VERSION ""

NS_ :

BS_:
BU_: INV U2C HV_BMS ECU_FRONT ECU_REAR DSH TCU LV_BMS SGL
BO_ 560 BrakePressure: 4 ECU_FRONT
   SG_ BrakeSensor1 : 0|16@1- (0.1,0) [0|0] "psi" Vector__XXX
   SG_ BrakeSensor2 : 16|16@1- (0.1,0) [0|0] "psi" Vector__XXX

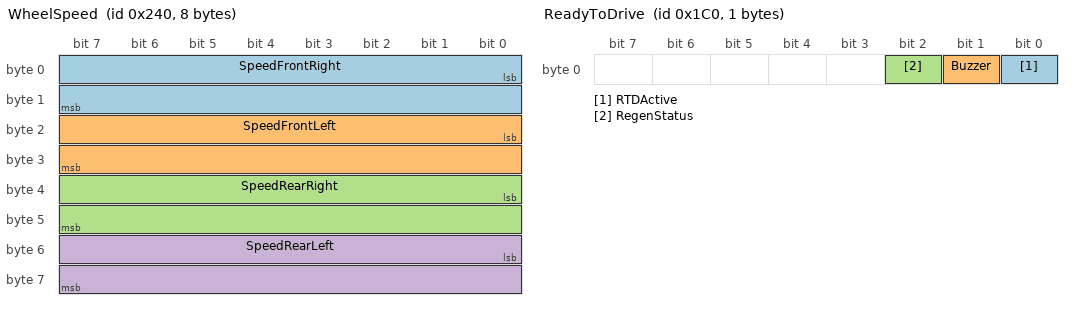
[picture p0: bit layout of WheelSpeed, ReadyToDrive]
BO_ 576 WheelSpeed: 8 ECU_FRONT
   SG_ SpeedFrontRight : 0|16@1- (1,0) [0|0] "rpm" Vector__XXX
   SG_ SpeedFrontLeft : 16|16@1- (1,0) [0|0] "rpm" Vector__XXX
   SG_ SpeedRearRight : 32|16@1- (1,0) [0|0] "rpm" Vector__XXX
   SG_ SpeedRearLeft : 48|16@1- (1,0) [0|0] "rpm" Vector__XXX

BO_ 608 MBRTempSens: 2 ECU_REAR
   SG_ Temperature : 0|12@1- (0.0625,0) [-40|128] "degC" Vector__XXX

BO_ 448 ReadyToDrive: 1 ECU_FRONT
   SG_ RTDActive : 0|1@1+ (1,0) [0|1] "" Vector__XXX
   SG_ Buzzer : 1|1@1+ (1,0) [0|1] "" Vector__XXX
   SG_ RegenStatus : 2|1@1+ (1,0) [0|1] "" Vector__XXX

BO_ 1280 CANHeartBeatLED: 1 ECU_REAR
   SG_ HeartBit : 0|1@1+ (1,0) [0|1] "" Vector__XXX

BO_ 688 APPS: 4 ECU_FRONT
   SG_ APPS1 : 0|16@1- (0.01,0) [0|0] "percent" Vector__XXX
   SG_ APPS2 : 16|16@1- (0.01,0) [0|0] "percent" Vector__XXX

BO_ 528 BrakeLight: 1 ECU_FRONT
   SG_ BrakeLightActive : 0|1@1+ (1,0) [0|1] "" Vector__XXX

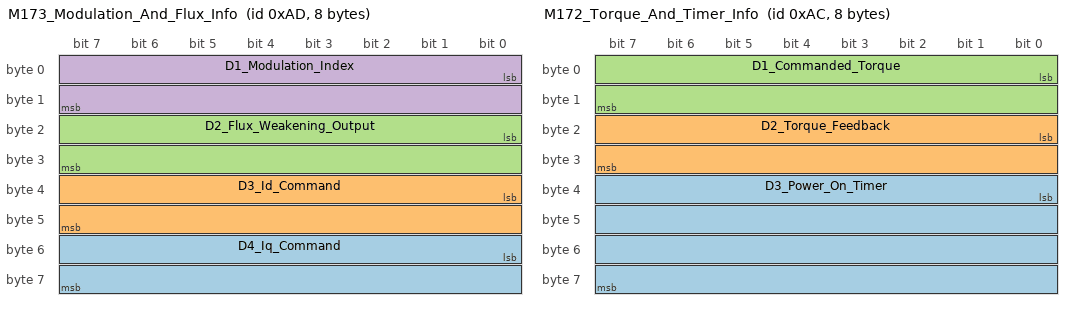
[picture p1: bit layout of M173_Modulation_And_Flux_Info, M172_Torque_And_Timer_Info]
BO_ 173 M173_Modulation_And_Flux_Info: 8 INV
   SG_ D4_Iq_Command : 48|16@1- (0.1,0) [-3276.8|3276.7] "A" Vector__XXX
   SG_ D3_Id_Command : 32|16@1- (0.1,0) [-3276.8|3276.7] "A" Vector__XXX
   SG_ D2_Flux_Weakening_Output : 16|16@1- (0.1,0) [-3276.8|3276.7] "A" Vector__XXX
   SG_ D1_Modulation_Index : 0|16@1- (0.0001,0) [-3.2768|3.2767] "" Vector__XXX

BO_ 172 M172_Torque_And_Timer_Info: 8 INV
   SG_ D3_Power_On_Timer : 32|32@1+ (0.003,0) [0|1.28848e+07] "sec" Vector__XXX
   SG_ D2_Torque_Feedback : 16|16@1- (0.1,0) [-3276.8|3276.7] "Nm" Vector__XXX
   SG_ D1_Commanded_Torque : 0|16@1- (0.1,0) [-3276.8|3276.7] "Nm" Vector__XXX

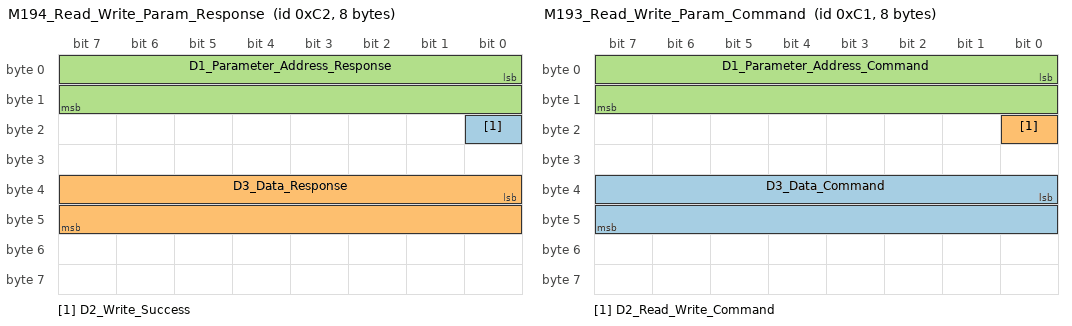
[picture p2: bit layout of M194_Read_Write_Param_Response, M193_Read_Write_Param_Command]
BO_ 194 M194_Read_Write_Param_Response: 8 INV
   SG_ D2_Write_Success : 16|1@1+ (1,0) [0|1] "" Vector__XXX
   SG_ D3_Data_Response : 32|16@1- (1,0) [-32768|32767] "" Vector__XXX
   SG_ D1_Parameter_Address_Response : 0|16@1+ (1,0) [0|65535] "" Vector__XXX

BO_ 193 M193_Read_Write_Param_Command: 8 ECU_FRONT
   SG_ D3_Data_Command : 32|16@1- (1,0) [-32768|32767] "" Vector__XXX
   SG_ D2_Read_Write_Command : 16|1@1+ (1,0) [0|1] "" Vector__XXX
   SG_ D1_Parameter_Address_Command : 0|16@1+ (1,0) [0|65535] "" Vector__XXX

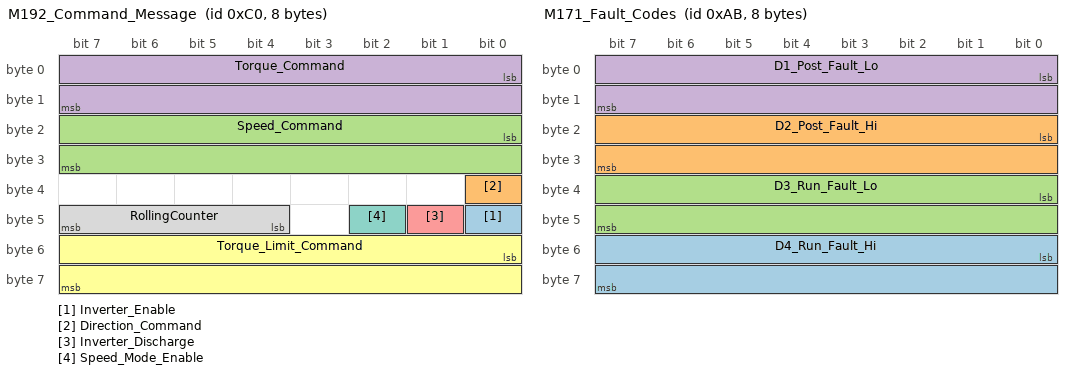
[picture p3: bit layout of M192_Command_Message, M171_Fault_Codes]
BO_ 192 M192_Command_Message: 8 ECU_FRONT
   SG_ Inverter_Enable : 40|1@1+ (1,0) [0|1] "Bit" Vector__XXX
   SG_ Direction_Command : 32|1@1+ (1,0) [0|1] "Bit" Vector__XXX
   SG_ Speed_Command : 16|16@1- (1,0) [-32768|32767] "rpm" Vector__XXX
   SG_ Torque_Command : 0|16@1- (0.1,0) [-3276.8|3276.7] "Nm" Vector__XXX
   SG_ Inverter_Discharge : 41|1@1+ (1,0) [0|1] "Bit" Vector__XXX
   SG_ Torque_Limit_Command : 48|16@1- (0.1,0) [-3276.8|3276.7] "Nm" Vector__XXX
   SG_ Speed_Mode_Enable : 42|1@1+ (1,0) [0|1] "Bit" Vector__XXX
   SG_ RollingCounter : 44|4@1+ (1,0) [0|15] "Bits" Vector__XXX

BO_ 171 M171_Fault_Codes: 8 INV
   SG_ D4_Run_Fault_Hi : 48|16@1+ (1,0) [0|65535] "" Vector__XXX
   SG_ D2_Post_Fault_Hi : 16|16@1+ (1,0) [0|65535] "" Vector__XXX
   SG_ D3_Run_Fault_Lo : 32|16@1+ (1,0) [0|65535] "" Vector__XXX
   SG_ D1_Post_Fault_Lo : 0|16@1+ (1,0) [0|65535] "" Vector__XXX

BO_ 170 M170_Internal_States: 8 INV
   SG_ D7_Direction_Command : 56|1@1+ (1,0) [0|1] "" Vector__XXX
   SG_ D6_Inverter_Enable_State : 48|1@1+ (1,0) [0|1] "" Vector__XXX
   SG_ D3_Relay_3_Status : 26|1@1+ (1,0) [0|1] "" Vector__XXX
   SG_ D3_Relay_4_Status : 27|1@1+ (1,0) [0|1] "" Vector__XXX
   SG_ D3_Relay_2_Status : 25|1@1+ (1,0) [0|1] "" Vector__XXX
   SG_ D4_Inverter_Run_Mode : 32|1@1+ (1,0) [0|1] "" Vector__XXX
   SG_ D5_Inverter_Command_Mode : 40|1@1+ (1,0) [0|1] "" Vector__XXX
   SG_ D3_Relay_1_Status : 24|1@1+ (1,0) [0|1] "" Vector__XXX
   SG_ D2_Inverter_State : 16|8@1+ (1,0) [0|255] "" Vector__XXX
   SG_ D1_VSM_State : 0|8@1+ (1,0) [0|15] "" Vector__XXX
   SG_ D6_Inverter_Enable_Lockout : 55|1@1+ (1,0) [0|1] "" Vector__XXX
   SG_ D4_Inverter_Discharge_State : 37|3@1+ (1,0) [0|7] "" Vector__XXX
   SG_ D3_Relay_5_Status : 28|1@1+ (1,0) [0|1] "" Vector__XXX
   SG_ D3_Relay_6_Status : 29|1@1+ (1,0) [0|1] "" Vector__XXX
   SG_ D7_BMS_Active : 57|1@1+ (1,0) [0|1] "" Vector__XXX
   SG_ D7_BMS_Torque_Limiting : 58|1@1+ (1,0) [0|1] "" Vector__XXX
   SG_ D7_Max_Speed_Limiting : 59|1@1+ (1,0) [0|1] "" Vector__XXX
   SG_ D7_Low_Speed_Limiting : 61|1@1+ (1,0) [0|1] "" Vector__XXX
   SG_ D5_Rolling_Counter : 44|4@1+ (1,0) [0|15] "" Vector__XXX
   SG_ D1_PWM_Frequency : 8|8@1+ (1,0) [0|255] "kHz" Vector__XXX
   SG_ D6_Start_Mode_Active : 54|1@1+ (1,0) [0|1] "" Vector__XXX

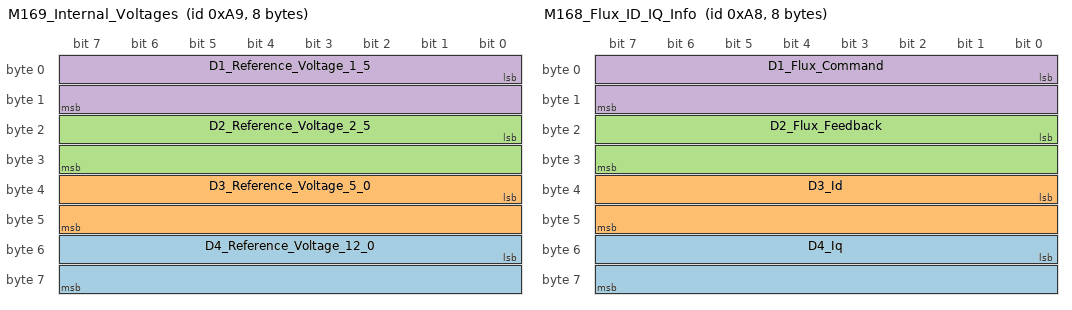
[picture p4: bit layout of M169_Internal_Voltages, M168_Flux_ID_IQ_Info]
BO_ 169 M169_Internal_Voltages: 8 INV
   SG_ D4_Reference_Voltage_12_0 : 48|16@1- (0.01,0) [-327.68|327.67] "V" Vector__XXX
   SG_ D3_Reference_Voltage_5_0 : 32|16@1- (0.01,0) [-327.68|327.67] "V" Vector__XXX
   SG_ D2_Reference_Voltage_2_5 : 16|16@1- (0.01,0) [-327.68|327.67] "V" Vector__XXX
   SG_ D1_Reference_Voltage_1_5 : 0|16@1- (0.01,0) [-327.68|327.67] "V" Vector__XXX

BO_ 168 M168_Flux_ID_IQ_Info: 8 INV
   SG_ D4_Iq : 48|16@1- (0.1,0) [-3276.8|3276.7] "A" Vector__XXX
   SG_ D3_Id : 32|16@1- (0.1,0) [-3276.8|3276.7] "A" Vector__XXX
   SG_ D2_Flux_Feedback : 16|16@1- (0.001,0) [-32.768|32.767] "Wb" Vector__XXX
   SG_ D1_Flux_Command : 0|16@1- (0.001,0) [-32.768|32.767] "Wb" Vector__XXX

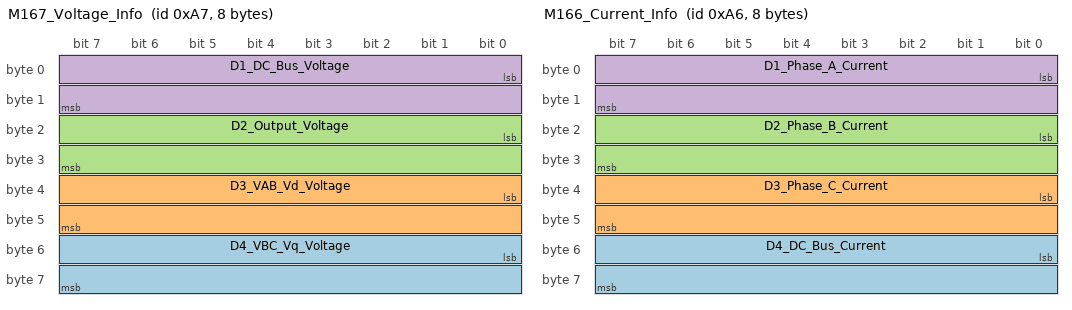
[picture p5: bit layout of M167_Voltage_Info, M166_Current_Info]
BO_ 167 M167_Voltage_Info: 8 INV
   SG_ D4_VBC_Vq_Voltage : 48|16@1- (0.1,0) [-3276.8|3276.7] "V" Vector__XXX
   SG_ D3_VAB_Vd_Voltage : 32|16@1- (0.1,0) [-3276.8|3276.7] "V" Vector__XXX
   SG_ D2_Output_Voltage : 16|16@1- (0.1,0) [-3276.8|3276.7] "V" Vector__XXX
   SG_ D1_DC_Bus_Voltage : 0|16@1- (0.1,0) [-3276.8|3276.7] "V" Vector__XXX

BO_ 166 M166_Current_Info: 8 INV
   SG_ D4_DC_Bus_Current : 48|16@1- (0.1,0) [-3276.8|3276.7] "A" Vector__XXX
   SG_ D3_Phase_C_Current : 32|16@1- (0.1,0) [-3276.8|3276.7] "A" Vector__XXX
   SG_ D2_Phase_B_Current : 16|16@1- (0.1,0) [-3276.8|3276.7] "A" Vector__XXX
   SG_ D1_Phase_A_Current : 0|16@1- (0.1,0) [-3276.8|3276.7] "A" Vector__XXX

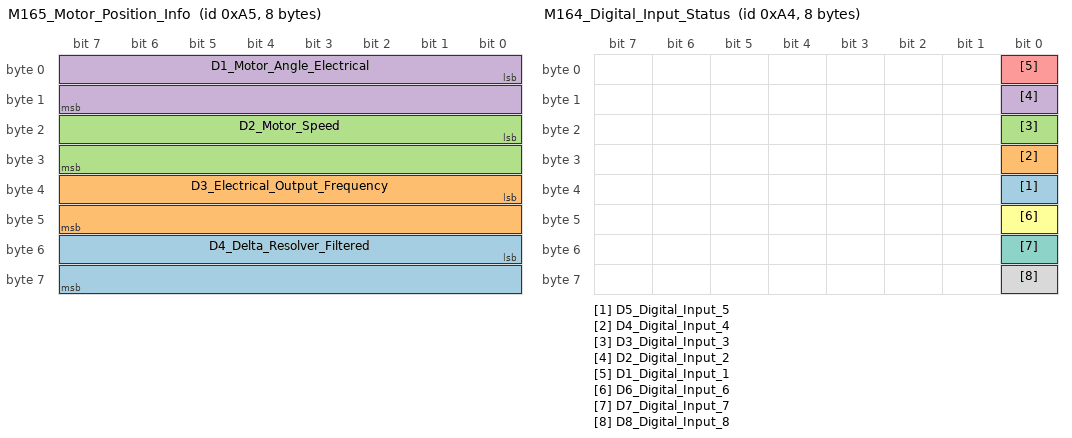
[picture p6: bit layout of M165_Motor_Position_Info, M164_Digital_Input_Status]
BO_ 165 M165_Motor_Position_Info: 8 INV
   SG_ D4_Delta_Resolver_Filtered : 48|16@1- (0.1,0) [-3276.8|3276.7] "deg" Vector__XXX
   SG_ D3_Electrical_Output_Frequency : 32|16@1- (0.1,0) [-3276.8|3276.7] "Hz" Vector__XXX
   SG_ D2_Motor_Speed : 16|16@1- (1,0) [-32768|32767] "rpm" Vector__XXX
   SG_ D1_Motor_Angle_Electrical : 0|16@1+ (0.1,0) [0|6553.5] "deg" Vector__XXX

BO_ 164 M164_Digital_Input_Status: 8 INV
   SG_ D5_Digital_Input_5 : 32|1@1+ (1,0) [0|1] "boolean" Vector__XXX
   SG_ D4_Digital_Input_4 : 24|1@1+ (1,0) [0|1] "boolean" Vector__XXX
   SG_ D3_Digital_Input_3 : 16|1@1+ (1,0) [0|1] "boolean" Vector__XXX
   SG_ D2_Digital_Input_2 : 8|1@1+ (1,0) [0|1] "boolean" Vector__XXX
   SG_ D1_Digital_Input_1 : 0|1@1+ (1,0) [0|1] "boolean" Vector__XXX
   SG_ D6_Digital_Input_6 : 40|1@1+ (1,0) [0|1] "boolean" Vector__XXX
   SG_ D7_Digital_Input_7 : 48|1@1+ (1,0) [0|1] "boolean" Vector__XXX
   SG_ D8_Digital_Input_8 : 56|1@1+ (1,0) [0|1] "boolean" Vector__XXX

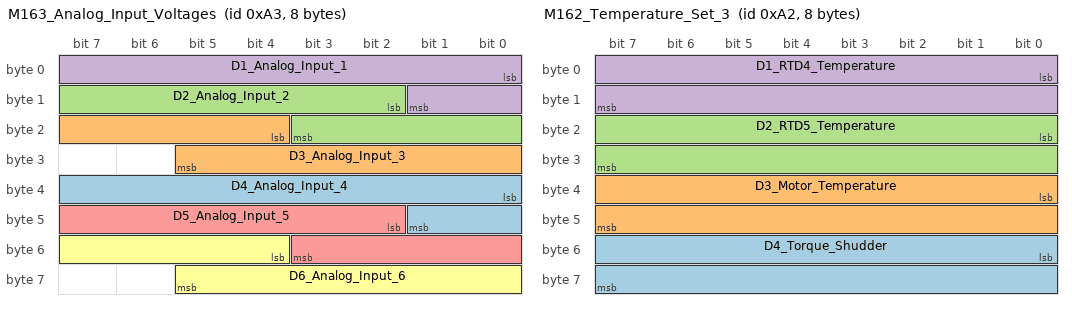
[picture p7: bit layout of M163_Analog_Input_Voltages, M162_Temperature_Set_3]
BO_ 163 M163_Analog_Input_Voltages: 8 INV
   SG_ D4_Analog_Input_4 : 32|10@1+ (0.01,0) [0|10.23] "V" Vector__XXX
   SG_ D3_Analog_Input_3 : 20|10@1+ (0.01,0) [0|10.23] "V" Vector__XXX
   SG_ D2_Analog_Input_2 : 10|10@1+ (0.01,0) [0|10.23] "V" Vector__XXX
   SG_ D1_Analog_Input_1 : 0|10@1+ (0.01,0) [0|10.23] "V" Vector__XXX
   SG_ D5_Analog_Input_5 : 42|10@1+ (0.01,0) [0|10.23] "V" Vector__XXX
   SG_ D6_Analog_Input_6 : 52|10@1+ (0.01,0) [0|10.23] "V" Vector__XXX

BO_ 162 M162_Temperature_Set_3: 8 INV
   SG_ D4_Torque_Shudder : 48|16@1- (0.1,0) [-3276.8|3276.7] "Nm" Vector__XXX
   SG_ D3_Motor_Temperature : 32|16@1- (0.1,0) [-3276.8|3276.7] "degC" Vector__XXX
   SG_ D2_RTD5_Temperature : 16|16@1- (0.1,0) [-3276.8|3276.7] "degC" Vector__XXX
   SG_ D1_RTD4_Temperature : 0|16@1- (0.1,0) [-3276.8|3276.7] "degC" Vector__XXX

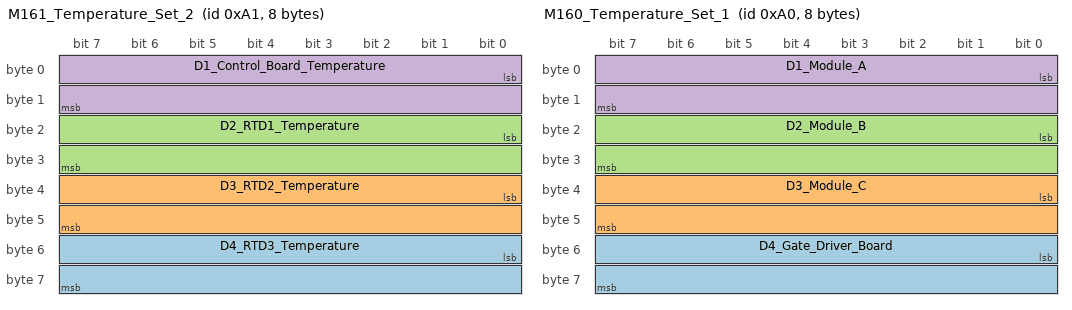
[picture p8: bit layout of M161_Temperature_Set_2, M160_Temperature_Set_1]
BO_ 161 M161_Temperature_Set_2: 8 INV
   SG_ D4_RTD3_Temperature : 48|16@1- (0.1,0) [-3276.8|3276.7] "degC" Vector__XXX
   SG_ D3_RTD2_Temperature : 32|16@1- (0.1,0) [-3276.8|3276.7] "degC" Vector__XXX
   SG_ D2_RTD1_Temperature : 16|16@1- (0.1,0) [-3276.8|3276.7] "degC" Vector__XXX
   SG_ D1_Control_Board_Temperature : 0|16@1- (0.1,0) [-3276.8|3276.7] "degC" Vector__XXX

BO_ 160 M160_Temperature_Set_1: 8 INV
   SG_ D4_Gate_Driver_Board : 48|16@1- (0.1,0) [-3276.8|3276.7] "degC" Vector__XXX
   SG_ D3_Module_C : 32|16@1- (0.1,0) [-3276.8|3276.7] "degC" Vector__XXX
   SG_ D2_Module_B : 16|16@1- (0.1,0) [-3276.8|3276.7] "degC" Vector__XXX
   SG_ D1_Module_A : 0|16@1- (0.1,0) [-3276.8|3276.7] "degC" Vector__XXX

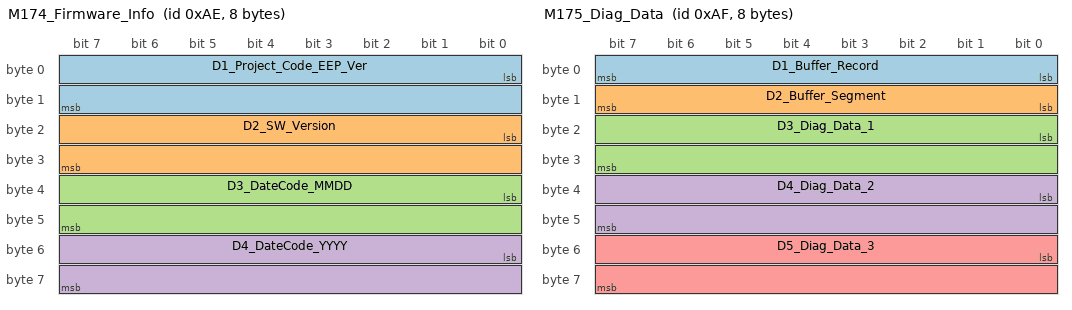
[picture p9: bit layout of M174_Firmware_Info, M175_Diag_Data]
BO_ 174 M174_Firmware_Info: 8 INV
   SG_ D1_Project_Code_EEP_Ver : 0|16@1+ (1,0) [0|65535] "" Vector__XXX
   SG_ D2_SW_Version : 16|16@1+ (1,0) [0|65535] "" Vector__XXX
   SG_ D3_DateCode_MMDD : 32|16@1+ (1,0) [0|65535] "" Vector__XXX
   SG_ D4_DateCode_YYYY : 48|16@1+ (1,0) [0|65535] "" Vector__XXX

BO_ 175 M175_Diag_Data: 8 INV
   SG_ D1_Buffer_Record : 0|8@1+ (1,0) [0|255] "" Vector__XXX
   SG_ D2_Buffer_Segment : 8|8@1+ (1,0) [0|5] "" Vector__XXX
   SG_ D3_Diag_Data_1 : 16|16@1- (1,0) [-32768|32767] "" Vector__XXX
   SG_ D4_Diag_Data_2 : 32|16@1- (1,0) [-32768|32767] "" Vector__XXX
   SG_ D5_Diag_Data_3 : 48|16@1- (1,0) [-32768|32767] "" Vector__XXX

BO_ 471 M187_U2C_Command_Txd: 8 INV
   SG_ D1_ID_Byte : 0|8@1+ (1,0) [0|255] "" Vector__XXX
   SG_ D2_Setpoint_Calc : 8|8@1+ (1,0) [0|255] "" Vector__XXX

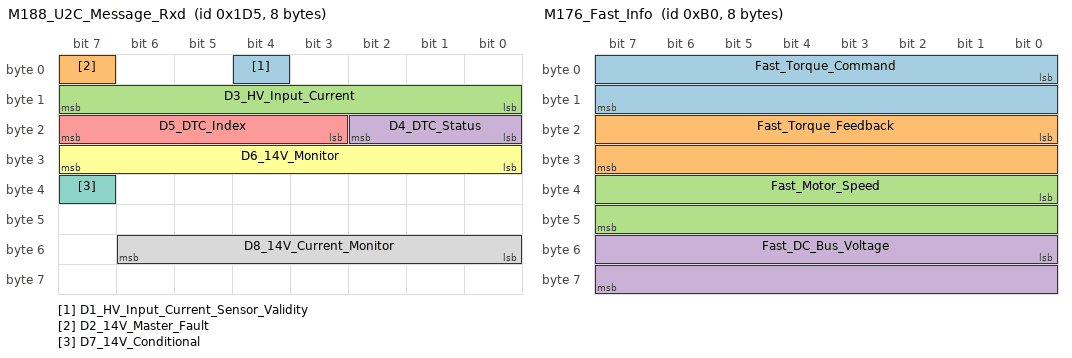
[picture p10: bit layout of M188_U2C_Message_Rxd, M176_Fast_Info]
BO_ 469 M188_U2C_Message_Rxd: 8 U2C
   SG_ D1_HV_Input_Current_Sensor_Validity : 4|1@1+ (1,0) [0|1] "" Vector__XXX
   SG_ D2_14V_Master_Fault : 7|1@1+ (1,0) [0|1] "" Vector__XXX
   SG_ D3_HV_Input_Current : 8|8@1+ (1,0) [0|255] "" Vector__XXX
   SG_ D4_DTC_Status : 16|3@1+ (1,0) [0|7] "" Vector__XXX
   SG_ D5_DTC_Index : 19|5@1+ (1,0) [0|31] "" Vector__XXX
   SG_ D6_14V_Monitor : 24|8@1+ (1,0) [0|255] "" Vector__XXX
   SG_ D7_14V_Conditional : 39|1@1+ (1,0) [0|1] "" Vector__XXX
   SG_ D8_14V_Current_Monitor : 48|7@1+ (1,0) [0|127] "" Vector__XXX

BO_ 176 M176_Fast_Info: 8 INV
   SG_ Fast_Torque_Command : 0|16@1- (0.1,0) [-3276.8|3276.7] "Nm" Vector__XXX
   SG_ Fast_Torque_Feedback : 16|16@1- (0.1,0) [-3276.8|3276.7] "Nm" Vector__XXX
   SG_ Fast_Motor_Speed : 32|16@1- (1,0) [-32768|32767] "rpm" Vector__XXX
   SG_ Fast_DC_Bus_Voltage : 48|16@1- (0.1,0) [-3276.8|3276.7] "V" Vector__XXX

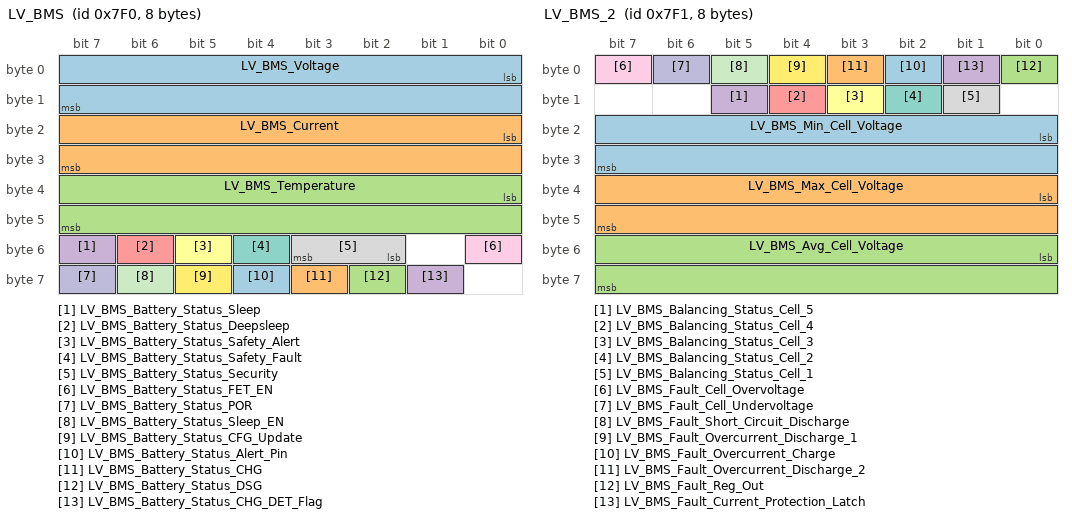
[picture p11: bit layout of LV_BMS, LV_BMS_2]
BO_ 2032 LV_BMS: 8 LV_BMS
   SG_ LV_BMS_Voltage : 0|16@1+ (1,0) [0|0] "mV" Vector__XXX
   SG_ LV_BMS_Current : 16|16@1- (1,0) [0|0] "mA" Vector__XXX
   SG_ LV_BMS_Temperature : 32|16@1+ (1,0) [0|0] "degC" Vector__XXX
   SG_ LV_BMS_Battery_Status_Sleep : 55|1@1+ (1,0) [0|1] "" Vector__XXX
   SG_ LV_BMS_Battery_Status_Deepsleep : 54|1@1+ (1,0) [0|1] "" Vector__XXX
   SG_ LV_BMS_Battery_Status_Safety_Alert : 53|1@1+ (1,0) [0|1] "" Vector__XXX
   SG_ LV_BMS_Battery_Status_Safety_Fault : 52|1@1+ (1,0) [0|1] "" Vector__XXX
   SG_ LV_BMS_Battery_Status_Security : 50|2@1+ (1,0) [0|1] "" Vector__XXX
   SG_ LV_BMS_Battery_Status_FET_EN : 48|1@1+ (1,0) [0|1] "" Vector__XXX
   SG_ LV_BMS_Battery_Status_POR : 63|1@1+ (1,0) [0|1] "" Vector__XXX
   SG_ LV_BMS_Battery_Status_Sleep_EN : 62|1@1+ (1,0) [0|1] "" Vector__XXX
   SG_ LV_BMS_Battery_Status_CFG_Update : 61|1@1+ (1,0) [0|1] "" Vector__XXX
   SG_ LV_BMS_Battery_Status_Alert_Pin : 60|1@1+ (1,0) [0|1] "" Vector__XXX
   SG_ LV_BMS_Battery_Status_CHG : 59|1@1+ (1,0) [0|1] "" Vector__XXX
   SG_ LV_BMS_Battery_Status_DSG : 58|1@1+ (1,0) [0|1] "" Vector__XXX
   SG_ LV_BMS_Battery_Status_CHG_DET_Flag : 57|1@1+ (1,0) [0|1] "" Vector__XXX

BO_ 2033 LV_BMS_2: 8 LV_BMS
   SG_ LV_BMS_Min_Cell_Voltage : 16|16@1+ (1,0) [0|0] "mV" Vector__XXX
   SG_ LV_BMS_Max_Cell_Voltage : 32|16@1+ (1,0) [0|0] "mV" Vector__XXX
   SG_ LV_BMS_Avg_Cell_Voltage : 48|16@1+ (1,0) [0|0] "mV" Vector__XXX
   SG_ LV_BMS_Balancing_Status_Cell_5 : 13|1@1+ (1,0) [0|0] "" Vector__XXX
   SG_ LV_BMS_Balancing_Status_Cell_4 : 12|1@1+ (1,0) [0|0] "" Vector__XXX
   SG_ LV_BMS_Balancing_Status_Cell_3 : 11|1@1+ (1,0) [0|0] "" Vector__XXX
   SG_ LV_BMS_Balancing_Status_Cell_2 : 10|1@1+ (1,0) [0|0] "" Vector__XXX
   SG_ LV_BMS_Balancing_Status_Cell_1 : 9|1@1+ (1,0) [0|0] "" Vector__XXX
   SG_ LV_BMS_Fault_Cell_Overvoltage : 7|1@1+ (1,0) [0|1] "" Vector__XXX
   SG_ LV_BMS_Fault_Cell_Undervoltage : 6|1@1+ (1,0) [0|1] "" Vector__XXX
   SG_ LV_BMS_Fault_Short_Circuit_Discharge : 5|1@1+ (1,0) [0|1] "" Vector__XXX
   SG_ LV_BMS_Fault_Overcurrent_Discharge_1 : 4|1@1+ (1,0) [0|1] "" Vector__XXX
   SG_ LV_BMS_Fault_Overcurrent_Charge : 2|1@1+ (1,0) [0|1] "" Vector__XXX
   SG_ LV_BMS_Fault_Overcurrent_Discharge_2 : 3|1@1+ (1,0) [0|1] "" Vector__XXX
   SG_ LV_BMS_Fault_Reg_Out : 0|1@1+ (1,0) [0|1] "" Vector__XXX
   SG_ LV_BMS_Fault_Current_Protection_Latch : 1|1@1+ (1,0) [0|1] "" Vector__XXX

BO_ 195 BMS_Fault: 4 HV_BMS
   SG_ SEG1OV : 0|1@1+ (1,0) [0|1] "" Vector__XXX
   SG_ SEG1UV : 1|1@1+ (1,0) [0|1] "" Vector__XXX
   SG_ SEG1OT : 2|1@1+ (1,0) [0|1] "" Vector__XXX
   SG_ SEG1UT : 3|1@1+ (1,0) [0|1] "" Vector__XXX
   SG_ SEG2OV : 4|1@1+ (1,0) [0|1] "" Vector__XXX
   SG_ SEG2UV : 5|1@1+ (1,0) [0|1] "" Vector__XXX
   SG_ SEG2OT : 6|1@1+ (1,0) [0|1] "" Vector__XXX
   SG_ SEG2UT : 7|1@1+ (1,0) [0|1] "" Vector__XXX
   SG_ SEG3OV : 8|1@1+ (1,0) [0|1] "" Vector__XXX
   SG_ SEG3UV : 9|1@1+ (1,0) [0|1] "" Vector__XXX
   SG_ SEG3OT : 10|1@1+ (1,0) [0|1] "" Vector__XXX
   SG_ SEG3UT : 11|1@1+ (1,0) [0|1] "" Vector__XXX
   SG_ SEG4OV : 12|1@1+ (1,0) [0|1] "" Vector__XXX
   SG_ SEG4UV : 13|1@1+ (1,0) [0|1] "" Vector__XXX
   SG_ SEG4OT : 14|1@1+ (1,0) [0|1] "" Vector__XXX
   SG_ SEG4UT : 15|1@1+ (1,0) [0|1] "" Vector__XXX
   SG_ SEG5OV : 16|1@1+ (1,0) [0|1] "" Vector__XXX
   SG_ SEG5UV : 17|1@1+ (1,0) [0|1] "" Vector__XXX
   SG_ SEG5OT : 18|1@1+ (1,0) [0|1] "" Vector__XXX
   SG_ SEG5UT : 19|1@1+ (1,0) [0|1] "" Vector__XXX
   SG_ SEG6OV : 20|1@1+ (1,0) [0|1] "" Vector__XXX
   SG_ SEG6UV : 21|1@1+ (1,0) [0|1] "" Vector__XXX
   SG_ SEG6OT : 22|1@1+ (1,0) [0|1] "" Vector__XXX
   SG_ SEG6UT : 23|1@1+ (1,0) [0|1] "" Vector__XXX
   SG_ PACKOC : 24|1@1+ (1,0) [0|1] "" Vector__XXX
   SG_ IMD_Fault : 25|1@1+ (1,0) [0|1] "" Vector__XXX
   SG_ PEC_ERROR : 26|1@1+ (1,0) [0|1] "" Vector__XXX

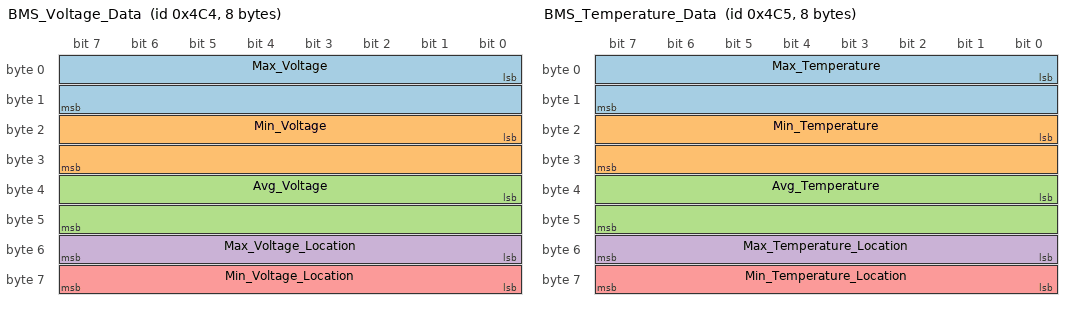
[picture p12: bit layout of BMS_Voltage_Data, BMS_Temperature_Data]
BO_ 1220 BMS_Voltage_Data: 8 HV_BMS
   SG_ Max_Voltage : 0|16@1- (0.00015,1.5) [0|0] "V" Vector__XXX
   SG_ Min_Voltage : 16|16@1- (0.00015,1.5) [0|0] "V" Vector__XXX
   SG_ Avg_Voltage : 32|16@1- (0.00015,1.5) [0|0] "V" Vector__XXX
   SG_ Max_Voltage_Location : 48|8@1+ (1,0) [0|0] "" Vector__XXX
   SG_ Min_Voltage_Location : 56|8@1+ (1,0) [0|0] "" Vector__XXX

BO_ 1221 BMS_Temperature_Data: 8 HV_BMS
   SG_ Max_Temperature : 0|16@1- (0.01,0) [0|0] "degC" Vector__XXX
   SG_ Min_Temperature : 16|16@1- (0.01,0) [0|0] "degC" Vector__XXX
   SG_ Avg_Temperature : 32|16@1- (0.01,0) [0|0] "degC" Vector__XXX
   SG_ Max_Temperature_Location : 48|8@1+ (1,0) [0|0] "" Vector__XXX
   SG_ Min_Temperature_Location : 56|8@1+ (1,0) [0|0] "" Vector__XXX

BO_ 1222 BMS_Pack_Data: 4 HV_BMS
   SG_ Pack_Voltage : 0|16@1+ (0.01,0) [0|0] "V" Vector__XXX
   SG_ Pack_Current : 16|16@1- (0.01,0) [0|0] "A" Vector__XXX

BO_ 1300 CAN_Bus_Data: 2 TCU
   SG_ Bus_Load : 0|16@1+ (0.01,0) [0|0] "percent" Vector__XXX

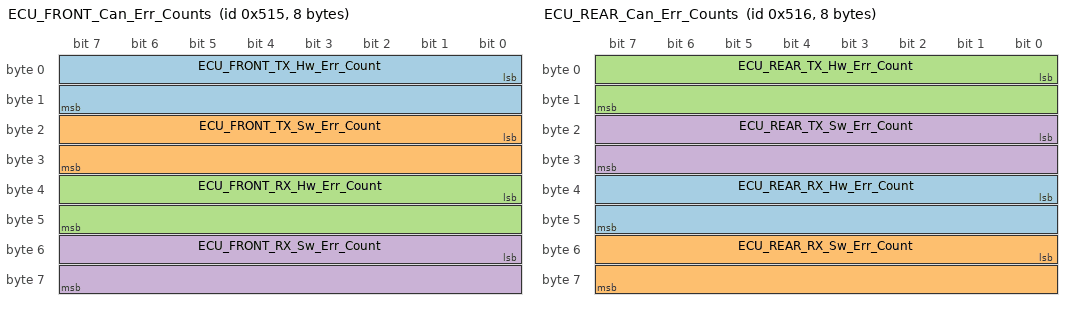
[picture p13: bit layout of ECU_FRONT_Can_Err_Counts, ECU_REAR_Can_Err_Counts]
BO_ 1301 ECU_FRONT_Can_Err_Counts: 8 ECU_FRONT
   SG_ ECU_FRONT_TX_Hw_Err_Count : 0|16@1+ (1,0) [0|0] "Errors" Vector__XXX
   SG_ ECU_FRONT_TX_Sw_Err_Count : 16|16@1+ (1,0) [0|0] "Errors" Vector__XXX
   SG_ ECU_FRONT_RX_Hw_Err_Count : 32|16@1+ (1,0) [0|0] "Errors" Vector__XXX
   SG_ ECU_FRONT_RX_Sw_Err_Count : 48|16@1+ (1,0) [0|0] "Errors" Vector__XXX

BO_ 656 ECU_REAR_Brake_Temp: 3 ECU_REAR
   SG_ ECU_REAR_Brake_Temp_RR : 0|10@1+ (1,0) [0|800] "degC" Vector__XXX
   SG_ ECU_REAR_Brake_Temp_RL : 10|10@1+ (1,0) [0|800] "degC" Vector__XXX

BO_ 640 ECU_FRONT_BrakeTemp: 3 ECU_FRONT
   SG_ ECU_FRONT_BrakeTemp_FR : 0|10@1+ (1,0) [0|800] "degC" Vector__XXX
   SG_ ECU_FRONT_BrakeTemp_FL : 10|10@1+ (1,0) [0|800] "degC" Vector__XXX

BO_ 1302 ECU_REAR_Can_Err_Counts: 8 ECU_REAR
   SG_ ECU_REAR_RX_Hw_Err_Count : 32|16@1+ (1,0) [0|0] "Errors" Vector__XXX
   SG_ ECU_REAR_RX_Sw_Err_Count : 48|16@1+ (1,0) [0|0] "Errors" Vector__XXX
   SG_ ECU_REAR_TX_Hw_Err_Count : 0|16@1+ (1,0) [0|0] "Errors" Vector__XXX
   SG_ ECU_REAR_TX_Sw_Err_Count : 16|16@1+ (1,0) [0|0] "Errors" Vector__XXX

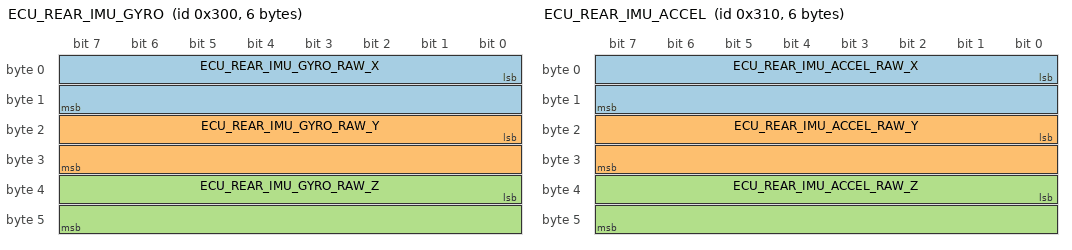
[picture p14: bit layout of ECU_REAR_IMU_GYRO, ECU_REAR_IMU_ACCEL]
BO_ 768 ECU_REAR_IMU_GYRO: 6 ECU_REAR
   SG_ ECU_REAR_IMU_GYRO_RAW_X : 0|16@1- (0.1,0) [-3276.8|3276.7] "deg/s" Vector__XXX
   SG_ ECU_REAR_IMU_GYRO_RAW_Y : 16|16@1- (0.1,0) [-3276.8|3276.7] "deg/s" Vector__XXX
   SG_ ECU_REAR_IMU_GYRO_RAW_Z : 32|16@1- (0.1,0) [-3276.6|3276.7] "deg/s" Vector__XXX

BO_ 784 ECU_REAR_IMU_ACCEL: 6 ECU_REAR
   SG_ ECU_REAR_IMU_ACCEL_RAW_X : 0|16@1- (0.001,0) [-32.768|32.767] "g" Vector__XXX
   SG_ ECU_REAR_IMU_ACCEL_RAW_Y : 16|16@1- (0.001,0) [-32.768|32.767] "g" Vector__XXX
   SG_ ECU_REAR_IMU_ACCEL_RAW_Z : 32|16@1- (0.001,0) [-32.768|32.767] "g" Vector__XXX

BO_ 592 SteeringPot: 2 ECU_FRONT
   SG_ SteeringPotAngle : 0|12@1- (0.1,0) [0|0] "" Vector__XXX

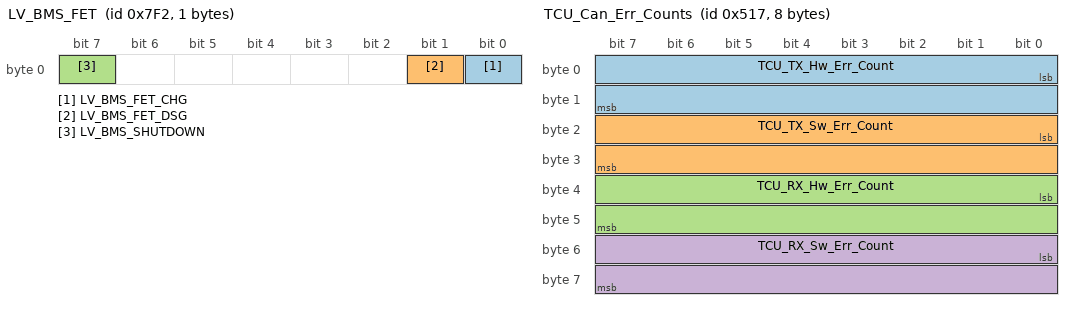
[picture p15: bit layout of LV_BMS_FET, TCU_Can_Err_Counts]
BO_ 2034 LV_BMS_FET: 1 LV_BMS
   SG_ LV_BMS_FET_CHG : 0|1@1+ (1,0) [0|1] "" Vector__XXX
   SG_ LV_BMS_FET_DSG : 1|1@1+ (1,0) [0|1] "" Vector__XXX
   SG_ LV_BMS_SHUTDOWN : 7|1@1+ (1,0) [0|1] "" Vector__XXX

BO_ 1303 TCU_Can_Err_Counts: 8 TCU
   SG_ TCU_TX_Hw_Err_Count : 0|16@1+ (1,0) [0|0] "Errors" Vector__XXX
   SG_ TCU_TX_Sw_Err_Count : 16|16@1+ (1,0) [0|0] "Errors" Vector__XXX
   SG_ TCU_RX_Hw_Err_Count : 32|16@1+ (1,0) [0|0] "Errors" Vector__XXX
   SG_ TCU_RX_Sw_Err_Count : 48|16@1+ (1,0) [0|0] "Errors" Vector__XXX

BO_ 800 SGL_Strain_Gauges_1_2: 8 SGL
   SG_ SGL_Strain_Gauge_1 : 0|32@1+ (1,0) [0|0] "" Vector__XXX
   SG_ SGL_Strain_Gauge_2 : 32|32@1+ (1,0) [0|0] "" Vector__XXX

BO_ 801 SGL_Strain_Gauges_3_4: 8 SGL
   SG_ SGL_Strain_Gauge_3 : 0|32@1+ (1,0) [0|0] "" Vector__XXX
   SG_ SGL_Strain_Gauge_4 : 32|32@1+ (1,0) [0|0] "" Vector__XXX

BO_ 802 SGL_Strain_Gauges_5_6: 8 SGL
   SG_ SGL_Strain_Gauge_5 : 0|32@1+ (1,0) [0|0] "" Vector__XXX
   SG_ SGL_Strain_Gauge_6 : 32|32@1+ (1,0) [0|0] "" Vector__XXX

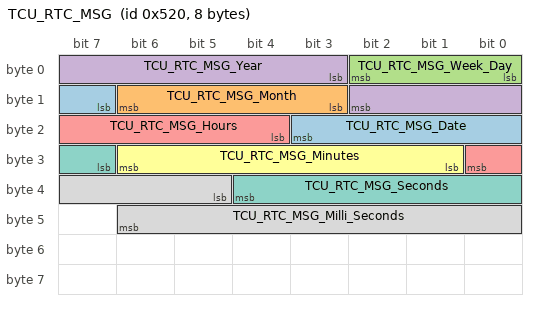
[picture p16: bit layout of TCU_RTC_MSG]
BO_ 1312 TCU_RTC_MSG: 8 TCU
   SG_ TCU_RTC_MSG_Date : 15|5@1+ (1,0) [0|31] "" Vector__XXX
   SG_ TCU_RTC_MSG_Month : 11|4@1+ (1,0) [1|12] "" Vector__XXX
   SG_ TCU_RTC_MSG_Week_Day : 0|3@1+ (1,0) [1|7] "" Vector__XXX
   SG_ TCU_RTC_MSG_Year : 3|8@1+ (1,0) [0|99] "" Vector__XXX
   SG_ TCU_RTC_MSG_Hours : 20|5@1+ (1,0) [0|23] "" Vector__XXX
   SG_ TCU_RTC_MSG_Minutes : 25|6@1+ (1,0) [0|59] "" Vector__XXX
   SG_ TCU_RTC_MSG_Seconds : 31|6@1+ (1,0) [0|59] "" Vector__XXX
   SG_ TCU_RTC_MSG_Milli_Seconds : 37|10@1+ (1,0) [0|999] "" Vector__XXX

BO_ 1313 TCU_RTC_REQ: 1 TCU
   SG_ TCU_RTC_REQ_Sig : 0|1@1+ (1,0) [0|1] "" Vector__XXX

CM_ BU_ INV "The Cascadia Motion inverter";
CM_ BU_ U2C "Delphi DC/DC Converter";
CM_ BU_ HV_BMS "High Voltage Battery Management System";
CM_ BU_ ECU_FRONT "Electronic Control Unit on Megaboard Front";
CM_ BU_ ECU_REAR "Electronic Control Unit on Megaboard Rear";
CM_ BU_ DSH "Aim Dashboard";
CM_ BU_ TCU "Telematics Control Unit on Megaboard Rear";
CM_ BU_ LV_BMS "Low Voltage Battery Management System";
CM_ BU_ SGL "Strain Gauge Logger";
CM_ SG_ 173 D4_Iq_Command "The commanded Q-axis current";
CM_ SG_ 173 D3_Id_Command "The commanded D-axis current";
CM_ SG_ 173 D2_Flux_Weakening_Output "This is the current output of the flux regulator.";
CM_ SG_ 173 D1_Modulation_Index "This is the modulation index. The scale factor is x100. To get the actual modulation index divide the value by 100.";
CM_ SG_ 172 D3_Power_On_Timer "Updated every 3 msec. This will roll over in approximately 150 days!";
CM_ SG_ 172 D2_Torque_Feedback "Estimated motor torque feedback";
CM_ SG_ 172 D1_Commanded_Torque "The commanded Torque";
CM_ BO_ 194 "The inverter response to each Parameter message that is received.";
CM_ SG_ 194 D2_Write_Success "0=Write failure, 1=Success";
CM_ SG_ 194 D3_Data_Response "All EEPROM data is 16 bits and is contained in bytes 4 and 5. Bytes 6 and 7 should be ignored.";
CM_ SG_ 194 D1_Parameter_Address_Response "Valid EEPROM Parameter CAN addresses are between 100 and 499.";
CM_ BO_ 193 "Parameter Message sent as needed by VCU to request info, change EEPROM, or command a function.";
CM_ SG_ 193 D3_Data_Command "All EEPROM data is 16 bits and is contained in bytes 4 and 5.";
CM_ SG_ 193 D2_Read_Write_Command "0=Read, 1=Write";
CM_ SG_ 193 D1_Parameter_Address_Command "Valid EEPROM Parameter CAN addresses are between 100 and 499.";
CM_ BO_ 192 "The command message is used to transmit data to the controller. This message is sent from a user supplied external controller to the PMxxx controller.";
CM_ SG_ 192 Inverter_Enable "0=Inverter OFF, 1 = Inverter ON";
CM_ SG_ 192 Direction_Command "0=CW, 1=CCW as veiwed from the shaft end of the motor";
CM_ SG_ 192 Speed_Command "Speed commandused when in speed mode";
CM_ SG_ 192 Torque_Command "Torque command when in torque mode";
CM_ SG_ 192 Inverter_Discharge "0=Discharge_Disable, 1=Discharge_Enable";
CM_ SG_ 192 Torque_Limit_Command "Torque Limit, set to 0 to keep default";
CM_ SG_ 192 Speed_Mode_Enable "0 = No change to mode, 1 = change to speed mode from torque mode";
CM_ SG_ 192 RollingCounter "Rolling Counter command";
CM_ SG_ 171 D4_Run_Fault_Hi "Each bit represents a fault. Please refer to PM100 Users Manual for details.";
CM_ SG_ 171 D2_Post_Fault_Hi "Each bit represents a fault. Please refer to PM100 Users Manual for details.";
CM_ SG_ 171 D3_Run_Fault_Lo "Each bit represents a fault. Please refer to PM100 Users Manual for details.";
CM_ SG_ 171 D1_Post_Fault_Lo "Each bit represents a fault. Please refer to PM100 Users Manual for details.";
CM_ SG_ 170 D7_Direction_Command "1 = Forward 0 = 'Reverse' if inverter enabled & 'Stopped' if inverter is disabled";
CM_ SG_ 170 D6_Inverter_Enable_State "0=Inverter Disabled, 1=Inverter Enabled";
CM_ SG_ 170 D3_Relay_3_Status "0=OFF, 1=ON";
CM_ SG_ 170 D3_Relay_4_Status "0=OFF, 1=ON";
CM_ SG_ 170 D3_Relay_2_Status "0=OFF, 1=ON";
CM_ SG_ 170 D4_Inverter_Run_Mode "0=Torque Mode, 1=Speed Mode";
CM_ SG_ 170 D5_Inverter_Command_Mode "0=CAN mode, 1=VSM mode";
CM_ SG_ 170 D3_Relay_1_Status "0=OFF, 1=ON";
CM_ SG_ 170 D2_Inverter_State "Different states for the inverter state machine";
CM_ SG_ 170 D1_VSM_State "Different states for the vehicle state machine";
CM_ SG_ 170 D6_Inverter_Enable_Lockout "0=Lockout Disabled, 1=Lockout Enabled";
CM_ SG_ 170 D4_Inverter_Discharge_State "0 = Disabled, 1 = Enabled, 2 = Speed Check, 3 = Active, 4 = Complete";
CM_ SG_ 170 D3_Relay_5_Status "0=OFF, 1=ON";
CM_ SG_ 170 D3_Relay_6_Status "0=OFF, 1=ON";
CM_ SG_ 170 D7_BMS_Active "0 = BMS Not Active, 1 = BMS Active";
CM_ SG_ 170 D7_BMS_Torque_Limiting "0 = Not Limiting, 1 = Limiting";
CM_ SG_ 170 D7_Max_Speed_Limiting "0 = Not Limiting, 1 = torque limiting due to maximum speed";
CM_ SG_ 170 D7_Low_Speed_Limiting "0 = Not Limiting, 1 = Current limiting due to low motor speed";
CM_ SG_ 170 D5_Rolling_Counter "The current rolling counter value.";
CM_ SG_ 170 D1_PWM_Frequency "The inverter PWM frequency";
CM_ SG_ 170 D6_Start_Mode_Active "If in Key Switch Mode 1 then indicates status of Start input being applied. 0 = not active, 1 = active";
CM_ SG_ 169 D4_Reference_Voltage_12_0 "12V Input Voltage";
CM_ SG_ 169 D3_Reference_Voltage_5_0 "Transducer voltage";
CM_ SG_ 169 D2_Reference_Voltage_2_5 "Internal reference voltage";
CM_ SG_ 169 D1_Reference_Voltage_1_5 "Internal reference voltage";
CM_ SG_ 168 D4_Iq "The measured Iq current";
CM_ SG_ 168 D3_Id "The measured Id current";
CM_ SG_ 168 D2_Flux_Feedback "The estimated flux";
CM_ SG_ 168 D1_Flux_Command "The commanded flux";
CM_ SG_ 167 D4_VBC_Vq_Voltage "Measured value of the voltage between Phase B and Phase C";
CM_ SG_ 167 D3_VAB_Vd_Voltage "Measured value of the voltage betwen phase A and Phase B";
CM_ SG_ 167 D2_Output_Voltage "The calculated value of the output voltage, in peak line-neutral volts";
CM_ SG_ 167 D1_DC_Bus_Voltage "The actual measured value of the DC bus voltage";
CM_ SG_ 166 D4_DC_Bus_Current "The Calculated DC Bus Current";
CM_ SG_ 166 D3_Phase_C_Current "The measured value of Phase C current";
CM_ SG_ 166 D2_Phase_B_Current "The measured value of Phase B current";
CM_ SG_ 166 D1_Phase_A_Current "The measured value of Phase A current";
CM_ SG_ 165 D4_Delta_Resolver_Filtered "Used in calibration of resolver angle adjustment.";
CM_ SG_ 165 D3_Electrical_Output_Frequency "The actual electrical frequency of the inverter";
CM_ SG_ 165 D2_Motor_Speed "The measured speed of the motor";
CM_ SG_ 165 D1_Motor_Angle_Electrical "The Electrical Angle of the motor as read by the encoder or resolver";
CM_ SG_ 164 D5_Digital_Input_5 "Status of Digital Input #5";
CM_ SG_ 164 D4_Digital_Input_4 "Status of Digital Input #4";
CM_ SG_ 164 D3_Digital_Input_3 "Status of Digital Input #3";
CM_ SG_ 164 D2_Digital_Input_2 "Status of Digital Input #2";
CM_ SG_ 164 D1_Digital_Input_1 "Status of Digital Input #1";
CM_ SG_ 164 D6_Digital_Input_6 "Status of Digital Input #6";
CM_ SG_ 164 D7_Digital_Input_7 "Status of Digital Input #7";
CM_ SG_ 164 D8_Digital_Input_8 "Status of Digital Input #8";
CM_ SG_ 163 D4_Analog_Input_4 "Voltage on Analog Input #4";
CM_ SG_ 163 D3_Analog_Input_3 "Voltage on Analog Input #3";
CM_ SG_ 163 D2_Analog_Input_2 "Voltage on Analog Input #2";
CM_ SG_ 163 D1_Analog_Input_1 "Voltage on Analog Input #1";
CM_ SG_ 163 D5_Analog_Input_5 "Voltage on Analog Input #5";
CM_ SG_ 163 D6_Analog_Input_6 "Voltage on Analog Input #6";
CM_ SG_ 162 D4_Torque_Shudder "Shudder compensation value of torque";
CM_ SG_ 162 D3_Motor_Temperature "Motor Temperature Sensor";
CM_ SG_ 162 D2_RTD5_Temperature "RTD 5 (PT1000) Temperature (Gen 2 only)";
CM_ SG_ 162 D1_RTD4_Temperature "RTD 4 (PT1000) Temperature (Gen 2 only)";
CM_ SG_ 161 D4_RTD3_Temperature "RTD input 3 (PT1000) Temperature (Gen 2 only)";
CM_ SG_ 161 D3_RTD2_Temperature "RTD input 2 (PT1000) Temperature";
CM_ SG_ 161 D2_RTD1_Temperature "RTD input 1 (PT1000) Temperature";
CM_ SG_ 161 D1_Control_Board_Temperature "Control Board Temperature";
CM_ SG_ 160 D4_Gate_Driver_Board "Gate Driver Board Temperature";
CM_ SG_ 160 D3_Module_C "IGBT Module C Temperature";
CM_ SG_ 160 D2_Module_B "IGBT Module B Temperature";
CM_ SG_ 160 D1_Module_A "IGBT Module A Temperature";
CM_ BO_ 471 "Enable message sent to Delphi DC/DC converter.";
CM_ BO_ 469 "Response from Delphi DC/DC converter.";
CM_ BO_ 176 "To enable fast message set CAN ACTIVE MSGS HI WORD to 0xFFFE. Setting to default value of 0xFFFF will disable the fast message.";
CM_ SG_ 176 Fast_Torque_Command "The commanded torque";
CM_ SG_ 176 Fast_Torque_Feedback "The estimated torque";
CM_ SG_ 176 Fast_Motor_Speed "Motor speed";
CM_ SG_ 176 Fast_DC_Bus_Voltage "DC Bus Voltage";
CM_ BO_ 2032 "Measurements for LV BMS";
CM_ BO_ 2033 "More Measurements for LV BMS";
CM_ BO_ 195 "HV BMS faults";
CM_ BO_ 1220 "HV battery cell voltages data";
CM_ BO_ 1221 "HV battery temperature data";
CM_ BO_ 1222 "HV battery pack data";
CM_ BO_ 1300 "CAN bus statistics";
CM_ BO_ 2034 "LV BMS control commands";
CM_ SG_ 2034 LV_BMS_FET_CHG "Charge";
CM_ SG_ 2034 LV_BMS_FET_DSG "Discharge";
CM_ SG_ 2034 LV_BMS_SHUTDOWN "Shutdown";
VAL_ 448 RTDActive 1 "ENABLE" 0 "DISABLE";
VAL_ 448 Buzzer 1 "ENABLE" 0 "DISABLE";
VAL_ 448 RegenStatus 0 "DISABLE" 1 "ENABLE";
VAL_ 1280 HeartBit 1 "ENABLE" 0 "DISABLE";
VAL_ 528 BrakeLightActive 1 "ENABLE" 0 "DISABLE";
